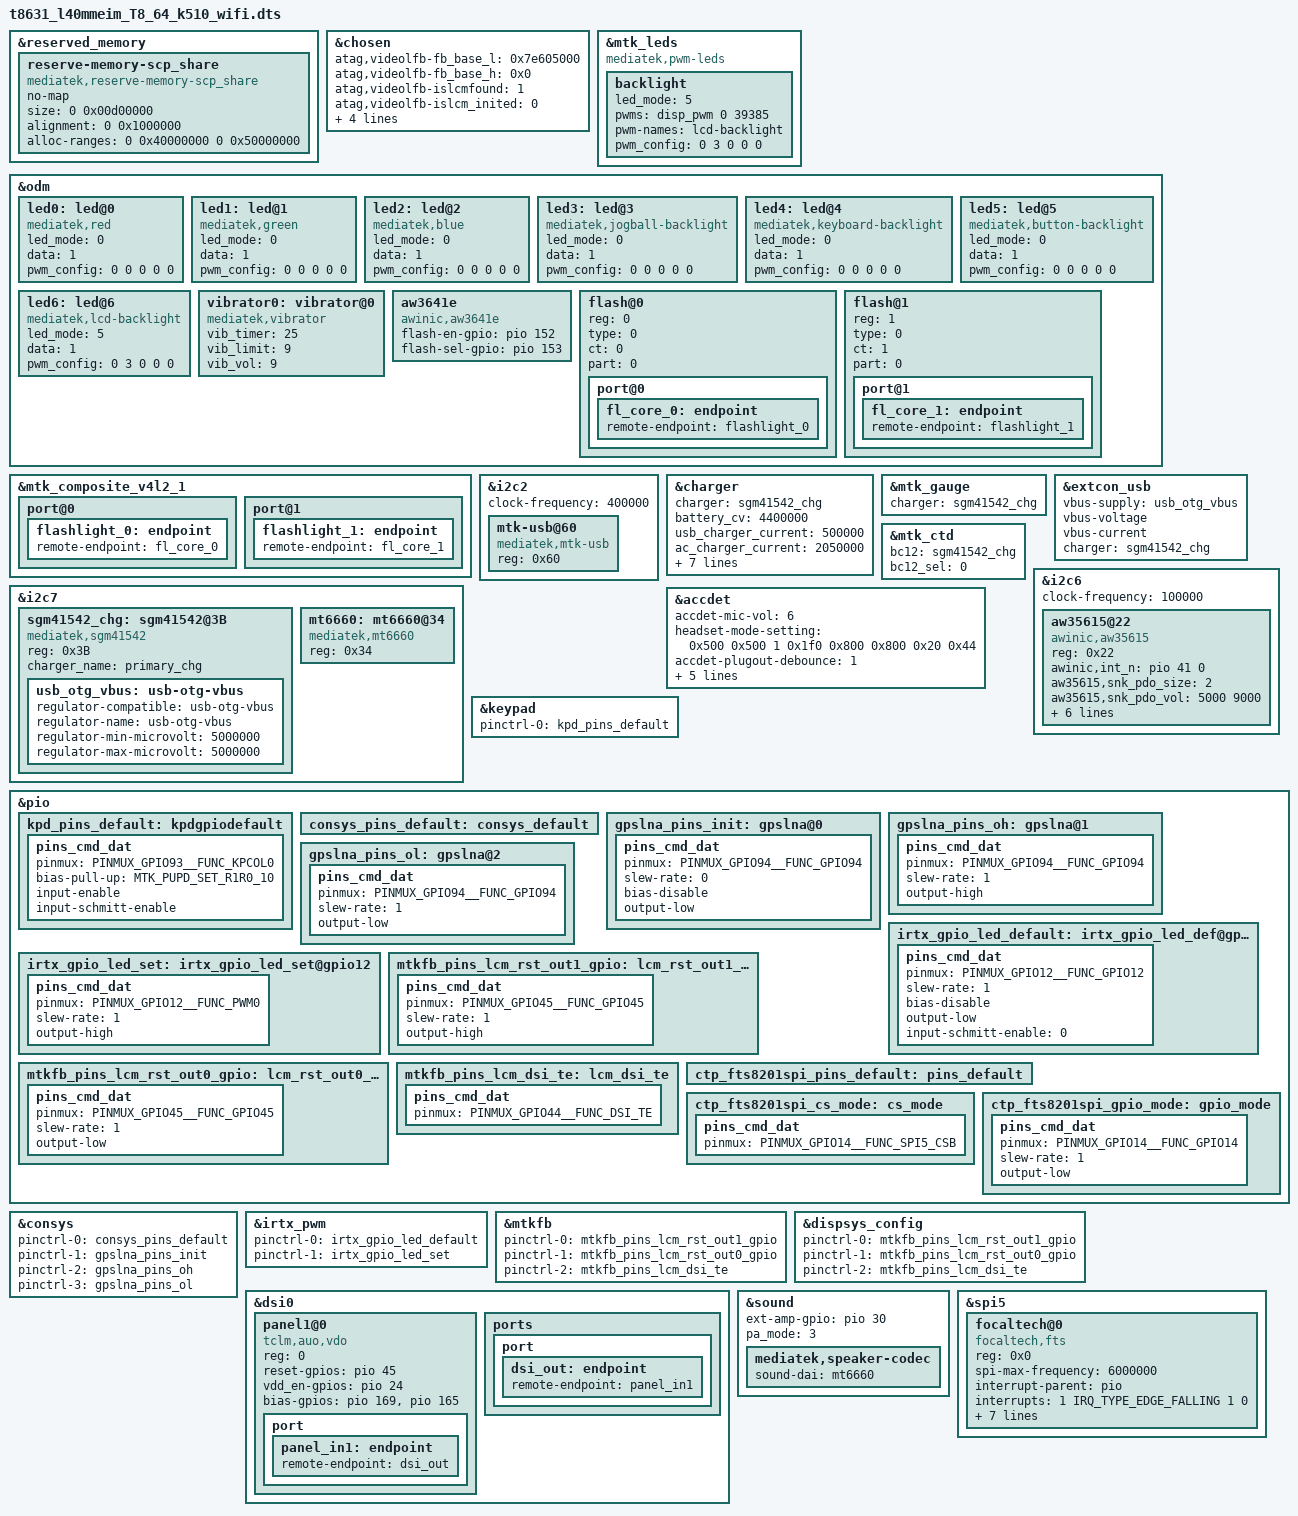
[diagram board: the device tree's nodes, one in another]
// SPDX-License-Identifier: GPL-2.0
/*
 * Copyright (c) 2019 MediaTek Inc.
 */

/dts-v1/;
/plugin/;
#include <dt-bindings/interrupt-controller/irq.h>
#include <dt-bindings/interrupt-controller/arm-gic.h>
#include <dt-bindings/pinctrl/mt6768-pinfunc.h>

&reserved_memory {
	reserve-memory-scp_share {
		compatible = "mediatek,reserve-memory-scp_share";
		no-map;
		size = <0 0x00d00000>;
		alignment = <0 0x1000000>;
		alloc-ranges = <0 0x40000000 0 0x50000000>;
	};
};

/* chosen */
&chosen {

	atag,videolfb-fb_base_l = <0x7e605000>;
	atag,videolfb-fb_base_h = <0x0>;
	atag,videolfb-islcmfound = <1>;
	atag,videolfb-islcm_inited = <0>;
	atag,videolfb-fps= <6000>;
	atag,videolfb-vramSize= <0x017e8000>;
	atag,videolfb-lcmname=
		"hx83112b_fhdp_dsi_cmd_auo_rt5081_drv";
};

&mtk_leds {
	compatible = "mediatek,pwm-leds";
	backlight {
		led_mode = <5>;
		pwms = <&disp_pwm 0 39385>;
		pwm-names = "lcd-backlight";
		pwm_config = <0 3 0 0 0>;
	};
};

&odm {
	led0:led@0 {
		compatible = "mediatek,red";
		led_mode = <0>;
		data = <1>;
		pwm_config = <0 0 0 0 0>;
	};
	led1:led@1 {
		compatible = "mediatek,green";
		led_mode = <0>;
		data = <1>;
		pwm_config = <0 0 0 0 0>;
	};
	led2:led@2 {
		compatible = "mediatek,blue";
		led_mode = <0>;
		data = <1>;
		pwm_config = <0 0 0 0 0>;
	};
	led3:led@3 {
		compatible = "mediatek,jogball-backlight";
		led_mode = <0>;
		data = <1>;
		pwm_config = <0 0 0 0 0>;
	};
	led4:led@4 {
		compatible = "mediatek,keyboard-backlight";
		led_mode = <0>;
		data = <1>;
		pwm_config = <0 0 0 0 0>;
	};
	led5:led@5 {
		compatible = "mediatek,button-backlight";
		led_mode = <0>;
		data = <1>;
		pwm_config = <0 0 0 0 0>;
	};
	led6:led@6 {
		compatible = "mediatek,lcd-backlight";
		led_mode = <5>;
		data = <1>;
		pwm_config = <0 3 0 0 0>;
	};
	vibrator0:vibrator@0 {
		compatible = "mediatek,vibrator";
		vib_timer = <25>;
		vib_limit = <9>;
		vib_vol= <9>;
	};
	/* aw3641e flash  */
	aw3641e:aw3641e {
		compatible = "awinic,aw3641e";
		flash-en-gpio = <&pio 152 0>;
		flash-sel-gpio = <&pio 153 0>;
		status = "okay";
	};
	flash@0{
		reg = <0>;
		type = <0>;
		ct = <0>;
		part = <0>;
		port@0 {
			fl_core_0: endpoint {
				remote-endpoint = <&flashlight_0>;
			};
		};
	};
	flash@1{
		reg = <1>;
		type = <0>;
		ct = <1>;
		part = <0>;
		port@1 {
			fl_core_1: endpoint {
				remote-endpoint = <&flashlight_1>;
			};
		};
	};
};

&mtk_composite_v4l2_1 {
	port@0 {
		flashlight_0: endpoint {
			remote-endpoint = <&fl_core_0>;
		};
	};
	port@1 {
		flashlight_1: endpoint {
			remote-endpoint = <&fl_core_1>;
		};
	};
};

&i2c2 {
	clock-frequency = <400000>;

	mtk-usb@60 {
		compatible = "mediatek,mtk-usb";
		reg = <0x60>;
		status = "okay";
	};
};

&charger {
	charger = <&sgm41542_chg>;
	battery_cv = <4400000>;
	/* charging current */
	usb_charger_current = <500000>;
	ac_charger_current = <2050000>;
	ac_charger_input_current = <2050000>;
	charging_host_charger_current = <1500000>;

	max_charger_voltage = <12000000>;

	/* dynamic mivr */
	enable_dynamic_mivr;
	min_charger_voltage_1 = <4400000>;
	min_charger_voltage_2 = <4400000>;
	max_dmivr_charger_current = <1800000>;
};

&mtk_gauge {
	charger = <&sgm41542_chg>;
};

&extcon_usb {
	status= "okay";
	vbus-supply = <&usb_otg_vbus>;
	vbus-voltage;
	vbus-current;
	charger = <&sgm41542_chg>;
};

&mtk_ctd {
	bc12 = <&sgm41542_chg>;
	bc12_sel = <0>;
};

&i2c7 {
	status = "okay";
	sgm41542_chg: sgm41542@3B {
		status = "okay";
		compatible = "mediatek,sgm41542";
		reg = <0x3B>;
		charger_name = "primary_chg";

		usb_otg_vbus: usb-otg-vbus {
			regulator-compatible = "usb-otg-vbus";
			regulator-name = "usb-otg-vbus";
			regulator-min-microvolt = <5000000>;
			regulator-max-microvolt = <5000000>;
		};
	};
	
#if 0
	sgm41513_chg: sgm41513@1A {
		status = "okay";
		compatible = "mediatek,sgm41513";
		reg = <0x1A>;
		/*charger_name = "secondary_chg";*/
		charger_name = "primary_chg";

		usb_otg_vbus: usb-otg-vbus {
			regulator-compatible = "usb-otg-vbus";
			regulator-name = "usb-otg-vbus";
			regulator-min-microvolt = <5000000>;
			regulator-max-microvolt = <5000000>;
		};
	};
#endif
};

&i2c6 {
	clock-frequency = <100000>;

	aw35615@22 {
		compatible = "awinic,aw35615";
		reg = <0x22>;
		awinic,int_n = <&pio 41 0>;
		aw35615,snk_pdo_size = <2>; /* set sink pdo num*/
		aw35615,snk_pdo_vol = <5000 9000>; /* set sink pdo voltage mV*/
		aw35615,snk_pdo_cur = <2000 2000>; /* set sink pdo current mA*/
		aw35615,src_pdo_size = <1>; /* set source pdo num*/
		aw35615,src_pdo_vol = <5000>; /* set source pdo voltage mV*/
		aw35615,src_pdo_cur = <1000>; /* set source pdo current mA*/
		aw35615,snk_tog_time = <0x38>; /* set toggle sink time */
		aw35615,src_tog_time = <0x24>; /* set toggle source time */
		status = "okay";
	};
	
#if 0
	husb311_typec: husb311@4e {
		compatible = "hynetek,husb311";
		reg = <0x4e>;
		status = "okay";
		
		interrupt-parent = <&pio>;
		//interrupts = <41 0x8>;
		tcpc-dual,supported_modes = <0>; /* 0: dfp/ufp, */
						 /* 1: dfp, 2: ufp */
		tcpc,name = "type_c_port0"; /* tcpc_device's name */
		tcpc,role_def = <4>; /* 0: SNK Only, 1: SRC Only, 2: DRP, */
					/* 3: Try.SRC, 4: Try.SNK */
		tcpc,rp_level = <2>; /* 0: Default, 1: 1.5, 2: 3.0 */
		tcpc,vconn_supply  = <0>;  /* 0: Never, 1: Always, */
					      /* 2: EMarkOnly, 3: StartOnly */
#if (CONFIG_MTK_GAUGE_VERSION == 30)
		tcpc,notifier_supply_num = <3>;
#else
		tcpc,notifier_supply_num = <2>;
#endif
		husb311pd,intr_gpio = <&pio 41 0x0>;
		husb311pd,intr_gpio_num = <41>;

		charger = <&sgm41542_chg>;

		pd-data {
			pd,vid = <0x2e99>;
			pd,pid = <0x0311>;
			pd,source-cap-ext = <0x171129cf 0x00000000 0x00000000
					     0x00000000 0x00000000 0x02000000>;
			pd,mfrs = "HynetekTCPC";

			/*
			 *	VSAFE5V = 0, MAX_POWER = 1, CUSTOM = 2,
			 *	MAX_POWER_LV = 0x21, MAX_POWER_LVIC = 0x31
			 *	MAX_POWER_HV = 0x41, MAX_POWER_HVIC = 0x51
			 */
			pd,charging_policy = <0x31>;

			/*
			 * Fixed 5V, 500 mA <0x00019032>
			 * Fixed 5V, 1A <0x00019064>
			 * Fixed 5V, 2A <0x000190c8>
			 * Fixed 5V, 3A <0x0001912c>
			 * Fixed 9V, 500 mA <0x0002d032>
			 * Fixed 9V, 1A <0x0002d064>
			 * Fixed 9V, 2A <0x0002d0c8>
			 * Fixed 9V, 3A <0x0002d12c>
			 * Fixed 12V,2A <0x0003c0c8>
			 * Variable 5-9V, 1A <0x8642d064>
			 * Variable 5-9V, 2A <0x8642d0c8>
			 * Variable 5-9V, 3A <0x8642d12c>
			 * PPS 3V~5.9V, 3A <0xC0761E3C>
			 */
			pd,source-pdo-size = <1>;
			pd,source-pdo-data = <0x00019032>;
			pd,sink-pdo-size = <1>;
			pd,sink-pdo-data = <0x0002d0c8>;

			/*
			 * No DP, host + device
			 *	pd,id-vdo-size = <3>;
			 *	pd,id-vdo-data = <0xd10029cf 0x0 0x17110000>;
			 * With DP
			 *	pd,id-vdo-size = <3>;
			 *	pd,id-vdo-data = <0xd60029cf 0x0 0x17110000
			 */

			pd,id-vdo-size = <3>;
			pd,id-vdo-data = <0xd10029cf 0x0 0x17110000>;

			bat,nr = <1>;
			pd,country_nr = <0>;

			bat-info0 {
				bat,vid = <0x29cf>;
				bat,pid = <0x1711>;
				bat,mfrs = "bat1";
				bat,design_cap = <3000>;
			};

			//bat-info1 {
			//	bat,vid = <0x8abc>;
			//	bat,pid = <0x5234>;
			//	bat,mfrs = "bat2";
			//	bat,design_cap = <4000>;
			//};

			//country0 {
			//	pd,country_code = <0x5457>;
			//	pd,country_len = <2>; /* max len = 26 */
			//	pd,country_data = <0xff 0xff>;
			//};

			//country1 {
			//	pd,country_code = <0x5553>;
			//	pd,country_len = <3>; /* max len = 26 */
			//	pd,country_data = <0xf1 0xf2 0xf3>;
			//};
		};
		dpm_caps {
			local_dr_power;
			local_dr_data;
			//local_ext_power;
			local_usb_comm;
			//local_usb_suspend;
			//local_high_cap;
			//local_give_back;
			local_no_suspend;
			local_vconn_supply;

			//attemp_discover_cable_dfp;
			attemp_enter_dp_mode;
			attemp_discover_cable;
			attemp_discover_id;

			/* 0: disable, 1: prefer_snk, 2: prefer_src */
			pr_check = <0>;
			//pr_reject_as_source;
			//pr_reject_as_sink;
			//pr_check_gp_source;
			//pr_check_gp_sink;

			/* 0: disable, 1: prefer_ufp, 2: prefer_dfp */
			dr_check = <0>;
			//dr_reject_as_dfp;
			//dr_reject_as_ufp;
		};
		displayport {
			/* connection type = "both", "ufp_d", "dfp_d" */
			1st_connection = "dfp_d";
			2nd_connection = "dfp_d";
			signal,dp_v13;
			//signal,dp_gen2;
			usbr20_not_used;
			typec,receptacle;
			ufp_d {
				//pin_assignment,mode_a;
				//pin_assignment,mode_b;
				//pin_assignment,mode_c;
				//pin_assignment,mode_d;
				//pin_assignment,mode_e;
			};
			dfp_d {
				/* Only support mode C & D */
				//pin_assignment,mode_a;
				//pin_assignment,mode_b;
				pin_assignment,mode_c;
				pin_assignment,mode_d;
				pin_assignment,mode_e;
				pin_assignment,mode_f;
			};
		};
	};
#endif
};


/* accdet start */
&accdet {
	/* accdet micbias voltage: 0x07,2.7v;0x05,2.5v;0x02,1.9v */
	accdet-mic-vol = <6>;
	headset-mode-setting = <0x500 0x500 1 0x1f0 0x800 0x800 0x20 0x44>;
	accdet-plugout-debounce = <1>;
	/*1:ACC mode, 2:low cost without in bias, 6:low cost with in bias*/
	accdet-mic-mode = <1>;
	/* eint_level_trigger: 8,LEVEL_LOW(DEF) ;4,LV_HIGH;others,LV_LOW */
	headset-eint-level-pol = <8>;
	/*0--MD_MAX--UP_MAX--DW_MAX*/
	headset-three-key-threshold = <0 80 220 400>;
	headset-three-key-threshold-CDD = <0 121 192 600>;
	/*0--MD_MAX--VOICE_MAX--UP_MAX--DW_MAX*/
	headset-four-key-threshold = <0 58 121 192 400>;
	status = "okay";
};
/* accdet end */

/* keypad start */
&keypad {
	pinctrl-names = "default";
	pinctrl-0 = <&kpd_pins_default>;
};

&pio {
	kpd_pins_default: kpdgpiodefault {
		pins_cmd_dat {
			pinmux = <PINMUX_GPIO93__FUNC_KPCOL0>;
			bias-pull-up = <MTK_PUPD_SET_R1R0_10>;
			input-enable;
			input-schmitt-enable;
		};
	};
};
/* keypad end */

/* CONSYS GPIO standardization */
&pio {
	consys_pins_default: consys_default {
	};
	gpslna_pins_init: gpslna@0 {
		pins_cmd_dat {
			pinmux = <PINMUX_GPIO94__FUNC_GPIO94>;
			slew-rate = <0>;
			bias-disable;
			output-low;
		};
	};
	gpslna_pins_oh: gpslna@1 {
		pins_cmd_dat {
			pinmux = <PINMUX_GPIO94__FUNC_GPIO94>;
			slew-rate = <1>;
			output-high;
		};
	};
	gpslna_pins_ol: gpslna@2 {
		pins_cmd_dat {
			pinmux = <PINMUX_GPIO94__FUNC_GPIO94>;
			slew-rate = <1>;
			output-low;
		};
	};
};
&consys {
	pinctrl-names = "default", "gps_lna_state_init",
		"gps_lna_state_oh", "gps_lna_state_ol";
	pinctrl-0 = <&consys_pins_default>;
	pinctrl-1 = <&gpslna_pins_init>;
	pinctrl-2 = <&gpslna_pins_oh>;
	pinctrl-3 = <&gpslna_pins_ol>;
	status = "okay";
};
/* CONSYS end */

/* IRTX GPIO Start */
&irtx_pwm {
	pinctrl-names = "irtx_gpio_led_default", "irtx_gpio_led_set";
	pinctrl-0 = <&irtx_gpio_led_default>;
	pinctrl-1 = <&irtx_gpio_led_set>;
	status = "okay";
};
&pio {
	/* IRTX GPIO Settings -Start */
	/* default: GPIO0, output, high */
	irtx_gpio_led_default:irtx_gpio_led_def@gpio12 {
		pins_cmd_dat {
			pinmux = <PINMUX_GPIO12__FUNC_GPIO12>;
			slew-rate = <1>;
			bias-disable;
			output-low;
			input-schmitt-enable = <0>;
		};
	};

	irtx_gpio_led_set:irtx_gpio_led_set@gpio12 {
		pins_cmd_dat {
			pinmux = <PINMUX_GPIO12__FUNC_PWM0>;
			slew-rate = <1>;
			output-high;
		};
	};
}; /* IRTX GPIO Settings -End */

/* DISPSYS GPIO standardization */
&pio {
	mtkfb_pins_lcm_rst_out1_gpio: lcm_rst_out1_gpio {
		pins_cmd_dat {
			pinmux = <PINMUX_GPIO45__FUNC_GPIO45>;
			slew-rate = <1>;
			output-high;
		};
	};

	mtkfb_pins_lcm_rst_out0_gpio: lcm_rst_out0_gpio {
		pins_cmd_dat {
			pinmux = <PINMUX_GPIO45__FUNC_GPIO45>;
			slew-rate = <1>;
			output-low;
		};
	};

	mtkfb_pins_lcm_dsi_te: lcm_dsi_te {
		pins_cmd_dat {
			pinmux = <PINMUX_GPIO44__FUNC_DSI_TE>;
		};
	};
};

&mtkfb {
	pinctrl-names =
		"lcm_rst_out1_gpio", "lcm_rst_out0_gpio",
		"mode_te_te";
	pinctrl-0 = <&mtkfb_pins_lcm_rst_out1_gpio>;
	pinctrl-1 = <&mtkfb_pins_lcm_rst_out0_gpio>;
	pinctrl-2 = <&mtkfb_pins_lcm_dsi_te>;
	status = "okay";
};

&dispsys_config {
	pinctrl-names =
		"lcm_rst_out1_gpio", "lcm_rst_out0_gpio",
		"mode_te_te";
	pinctrl-0 = <&mtkfb_pins_lcm_rst_out1_gpio>;
	pinctrl-1 = <&mtkfb_pins_lcm_rst_out0_gpio>;
	pinctrl-2 = <&mtkfb_pins_lcm_dsi_te>;
	status = "okay";
};

&dsi0 {
	status = "okay";
	#address-cells = <1>;
	#size-cells = <0>;
	panel1@0 {
		compatible = "tclm,auo,vdo";
		reg = <0>;
		reset-gpios = <&pio 45 0>;
		vdd_en-gpios = <&pio 24 0>;
		bias-gpios = <&pio 169 0>, <&pio 165 0>;
		pinctrl-names = "default";
		port {
			panel_in1: endpoint {
				remote-endpoint = <&dsi_out>;
			};
		};
	};
	ports {
		port {
			dsi_out: endpoint {
				remote-endpoint = <&panel_in1>;
			};
		};
	};
};

&i2c7 {
	mt6660: mt6660@34 {
		compatible = "mediatek,mt6660";
		#sound-dai-cells = <0>;
		reg = <0x34>;
		status = "okay";
	};
};

&sound {
	ext-amp-gpio = <&pio 30 0>;
	pa_mode = <3>;
	mediatek,speaker-codec {
		sound-dai = <&mt6660>;
	};
};

/* DISPSYS GPIO standardization end*/

/* TOUCH start */
&pio {
    ctp_fts8201spi_pins_default: pins_default {
    };

    ctp_fts8201spi_cs_mode: cs_mode {
        pins_cmd_dat {
            pinmux = <PINMUX_GPIO14__FUNC_SPI5_CSB>;
        };
    };
    ctp_fts8201spi_gpio_mode: gpio_mode {
        pins_cmd_dat {
            pinmux = <PINMUX_GPIO14__FUNC_GPIO14>;
            slew-rate = <1>;
            output-low;
        };
    };
};

&spi5 {
    status = "okay";
    #address-cells = <1>;
    #size-cells = <0>;
    focaltech@0 {
        compatible = "focaltech,fts";
        reg = <0x0>;
        spi-max-frequency = <6000000>;
        interrupt-parent = <&pio>;
        interrupts = <1 IRQ_TYPE_EDGE_FALLING 1 0>;
        focaltech,reset-gpio = <&pio 23 0>;
        focaltech,irq-gpio = <&pio 1 02>;
        focaltech,max-touch-number = <10>;
        focaltech,display-coords =  <0 0 1200 1920>;
        status = "okay";

        pinctrl-names = "pins_default", "cs_mode", "gpio_mode";
        pinctrl-0 = <&ctp_fts8201spi_pins_default>;
        pinctrl-1 = <&ctp_fts8201spi_cs_mode>;
        pinctrl-2 = <&ctp_fts8201spi_gpio_mode>;
    };
};
/* TOUCH end */

#include <t8631_l40mmeim_T8_64_k510_wifi/cust.dtsi>
#include "mediatek/cust_t8631_l40mmeim_T8_64_k510_wifi_camera.dtsi"
/*End of this file, DO NOT ADD ANYTHING HERE*/
